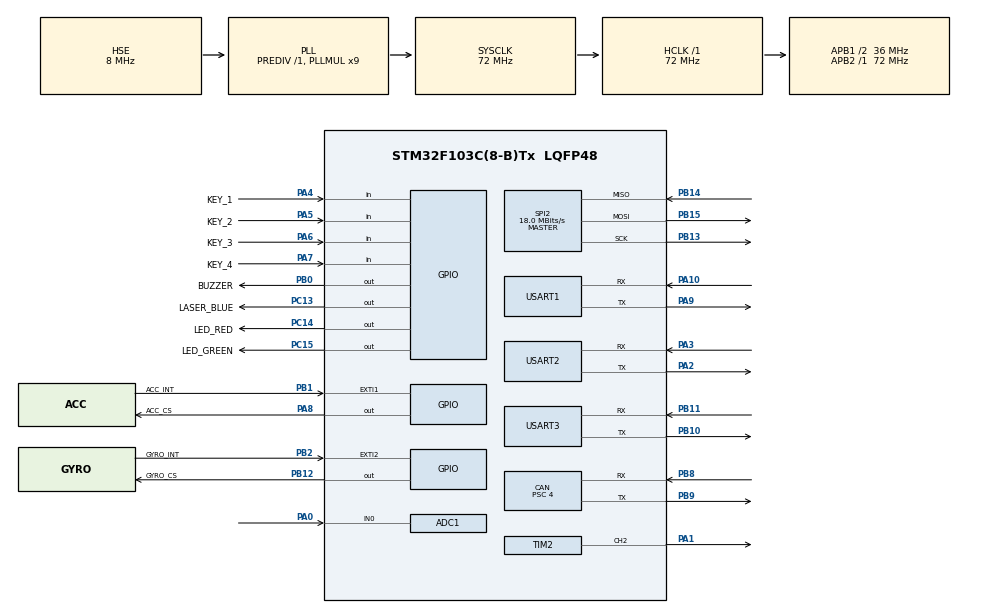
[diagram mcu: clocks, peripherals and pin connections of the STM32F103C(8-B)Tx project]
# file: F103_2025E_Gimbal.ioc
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ADC1.Channel-0\#ChannelRegularConversion=ADC_CHANNEL_0
ADC1.NbrOfConversionFlag=1
ADC1.Rank-0\#ChannelRegularConversion=1
ADC1.SamplingTime-0\#ChannelRegularConversion=ADC_SAMPLETIME_1CYCLE_5
ADC1.master=1
CAN.BS1=CAN_BS1_6TQ
CAN.BS2=CAN_BS2_2TQ
CAN.CalculateBaudRate=1000000
CAN.CalculateTimeBit=1000
CAN.CalculateTimeQuantum=111.11111111111111
CAN.Prescaler=4
Dma.Request0=USART2_RX
Dma.Request1=USART1_RX
Dma.USART1_RX.1.Direction=DMA_PERIPH_TO_MEMORY
Dma.USART1_RX.1.Instance=DMA1_Channel5
Dma.USART1_RX.1.MemDataAlignment=DMA_MDATAALIGN_BYTE
Dma.USART1_RX.1.MemInc=DMA_MINC_ENABLE
Dma.USART1_RX.1.Mode=DMA_NORMAL
Dma.USART1_RX.1.PeriphDataAlignment=DMA_PDATAALIGN_BYTE
Dma.USART1_RX.1.PeriphInc=DMA_PINC_DISABLE
Dma.USART1_RX.1.Priority=DMA_PRIORITY_LOW
Dma.USART2_RX.0.Direction=DMA_PERIPH_TO_MEMORY
Dma.USART2_RX.0.Instance=DMA1_Channel6
Dma.USART2_RX.0.MemDataAlignment=DMA_MDATAALIGN_BYTE
Dma.USART2_RX.0.MemInc=DMA_MINC_ENABLE
Dma.USART2_RX.0.Mode=DMA_NORMAL
Dma.USART2_RX.0.PeriphDataAlignment=DMA_PDATAALIGN_BYTE
Dma.USART2_RX.0.PeriphInc=DMA_PINC_DISABLE
Dma.USART2_RX.0.Priority=DMA_PRIORITY_LOW
FREERTOS.Tasks01=defaultTask,24,256,StartDefaultTask,Default,NULL,Static,defaultTaskBuffer,defaultTaskControlBlock;INSTask_rtos,48,256,IMU_task,As weak,NULL,Static,INSTask_rtosBuffer,INSTask_rtosControlBlock;GIMBALTask_rtos,24,256,GIMBAL_Task,As weak,NULL,Static,GIMBALTask_rtosBuffer,GIMBALTask_rtosControlBlock
FREERTOS.configENABLE_FPU=1
Mcu.Family=STM32F1
Mcu.Name=STM32F103C(8-B)Tx
Mcu.Package=LQFP48
NVIC.DMA1_Channel5_IRQn=true\:5\:0\:false\:false\:true\:true\:false\:true\:true
NVIC.DMA1_Channel6_IRQn=true\:5\:0\:false\:false\:true\:true\:false\:true\:true
NVIC.PriorityGroup=NVIC_PRIORITYGROUP_4
NVIC.TIM1_UP_IRQn=true\:15\:0\:false\:false\:true\:false\:false\:true\:true
NVIC.TimeBase=TIM1_UP_IRQn
NVIC.TimeBaseIP=TIM1
NVIC.USART1_IRQn=true\:5\:0\:false\:false\:true\:true\:true\:true\:true
NVIC.USART2_IRQn=true\:5\:0\:false\:false\:true\:true\:true\:true\:true
NVIC.USB_LP_CAN1_RX0_IRQn=true\:5\:0\:false\:false\:true\:true\:true\:true\:true
PA0-WKUP.Signal=ADCx_IN0
PA1.Signal=S_TIM2_CH2
PA10.Mode=Asynchronous
PA10.Signal=USART1_RX
PA13.Mode=Serial_Wire
PA13.Signal=SYS_JTMS-SWDIO
PA14.Mode=Serial_Wire
PA14.Signal=SYS_JTCK-SWCLK
PA2.Mode=Asynchronous
PA2.Signal=USART2_TX
PA3.Mode=Asynchronous
PA3.Signal=USART2_RX
PA4.GPIO_Label=KEY_1
PA4.Signal=GPIO_Input
PA5.GPIO_Label=KEY_2
PA5.Signal=GPIO_Input
PA6.GPIO_Label=KEY_3
PA6.Signal=GPIO_Input
PA7.GPIO_Label=KEY_4
PA7.Signal=GPIO_Input
PA8.GPIO_Label=ACC_CS
PA8.Signal=GPIO_Output
PA9.Mode=Asynchronous
PA9.Signal=USART1_TX
PB0.GPIO_Label=BUZZER
PB0.Signal=GPIO_Output
PB1.GPIO_Label=ACC_INT
PB1.Signal=GPXTI1
PB10.Mode=Asynchronous
PB10.Signal=USART3_TX
PB11.Mode=Asynchronous
PB11.Signal=USART3_RX
PB12.GPIO_Label=GYRO_CS
PB12.Signal=GPIO_Output
PB13.Mode=Full_Duplex_Master
PB13.Signal=SPI2_SCK
PB14.Mode=Full_Duplex_Master
PB14.Signal=SPI2_MISO
PB15.Mode=Full_Duplex_Master
PB15.Signal=SPI2_MOSI
PB2.GPIO_Label=GYRO_INT
PB2.Signal=GPXTI2
PB8.Mode=CAN_Activate
PB8.Signal=CAN_RX
PB9.Mode=CAN_Activate
PB9.Signal=CAN_TX
PC13-TAMPER-RTC.GPIO_Label=LASER_BLUE
PC13-TAMPER-RTC.Signal=GPIO_Output
PC14-OSC32_IN.GPIO_Label=LED_RED
PC14-OSC32_IN.Signal=GPIO_Output
PC15-OSC32_OUT.GPIO_Label=LED_GREEN
PC15-OSC32_OUT.Signal=GPIO_Output
PD0-OSC_IN.Mode=HSE-External-Oscillator
PD0-OSC_IN.Signal=RCC_OSC_IN
PD1-OSC_OUT.Mode=HSE-External-Oscillator
PD1-OSC_OUT.Signal=RCC_OSC_OUT
ProjectManager.HeapSize=0x400
ProjectManager.StackSize=0x400
ProjectManager.TargetToolchain=MDK-ARM V5.32
RCC.ADCPresc=RCC_ADCPCLK2_DIV6
RCC.AHBFreq_Value=72000000
RCC.APB1CLKDivider=RCC_HCLK_DIV2
RCC.APB1Freq_Value=36000000
RCC.APB1TimFreq_Value=72000000
RCC.APB2Freq_Value=72000000
RCC.APB2TimFreq_Value=72000000
RCC.HCLKFreq_Value=72000000
RCC.PLLMUL=RCC_PLL_MUL9
RCC.PLLSourceVirtual=RCC_PLLSOURCE_HSE
RCC.SYSCLKFreq_VALUE=72000000
RCC.SYSCLKSource=RCC_SYSCLKSOURCE_PLLCLK
RCC.USBFreq_Value=72000000
SH.ADCx_IN0.0=ADC1_IN0,IN0
SH.ADCx_IN0.1=ADC2_IN0
SH.S_TIM2_CH2.0=TIM2_CH2,PWM Generation2 CH2
SPI2.BaudRatePrescaler=SPI_BAUDRATEPRESCALER_2
SPI2.CalculateBaudRate=18.0 MBits/s
SPI2.Direction=SPI_DIRECTION_2LINES
SPI2.Mode=SPI_MODE_MASTER
SPI2.VirtualType=VM_MASTER
TIM2.Channel-PWM\ Generation2\ CH2=TIM_CHANNEL_2
USART1.VirtualMode=VM_ASYNC
USART2.VirtualMode=VM_ASYNC
USART3.VirtualMode=VM_ASYNC
VP_FREERTOS_VS_CMSIS_V2.Mode=CMSIS_V2
VP_SYS_VS_tim1.Mode=TIM1
VP_TIM2_VS_ClockSourceINT.Mode=Internal
board=custom

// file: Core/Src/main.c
/* USER CODE BEGIN Header */
/**
  ******************************************************************************
  * @file           : main.c
  * @brief          : Main program body
  ******************************************************************************
  * @attention
  *
  * Copyright (c) 2026 STMicroelectronics.
  * All rights reserved.
  *
  * This software is licensed under terms that can be found in the LICENSE file
  * in the root directory of this software component.
  * If no LICENSE file comes with this software, it is provided AS-IS.
  *
  ******************************************************************************
  */
/* USER CODE END Header */
#include "main.h"
#include "cmsis_os.h"
#include "adc.h"
#include "can.h"
#include "dma.h"
#include "spi.h"
#include "tim.h"
#include "usart.h"
#include "gpio.h"

/* USER CODE BEGIN Includes */
#include "gimbal.h"
/* USER CODE END Includes */

void SystemClock_Config(void);
void MX_FREERTOS_Init(void);

int main(void)
{

  /* MCU Configuration--------------------------------------------------------*/

  /* Reset of all peripherals, Initializes the Flash interface and the Systick. */
  HAL_Init();

  /* Configure the system clock */
  SystemClock_Config();

  /* Initialize all configured peripherals */
  MX_GPIO_Init();
  MX_DMA_Init();
  MX_ADC1_Init();
  MX_CAN_Init();
  MX_SPI2_Init();
  MX_TIM2_Init();
  MX_USART1_UART_Init();
  MX_USART2_UART_Init();
  MX_USART3_UART_Init();
  /* USER CODE BEGIN 2 */
  My_Main_Init();
  /* USER CODE END 2 */

  /* Init scheduler */
  osKernelInitialize();  /* Call init function for freertos objects (in cmsis_os2.c) */
  MX_FREERTOS_Init();

  /* Start scheduler */
  osKernelStart();

  /* We should never get here as control is now taken by the scheduler */

  /* Infinite loop */
  /* USER CODE BEGIN WHILE */
  while (1)
  {
    My_Main_Task();
    /* USER CODE END WHILE */

  }
}

void SystemClock_Config(void)
{
  RCC_OscInitTypeDef RCC_OscInitStruct = {0};
  RCC_ClkInitTypeDef RCC_ClkInitStruct = {0};
  RCC_PeriphCLKInitTypeDef PeriphClkInit = {0};

  /** Initializes the RCC Oscillators according to the specified parameters
  * in the RCC_OscInitTypeDef structure.
  */
  RCC_OscInitStruct.OscillatorType = RCC_OSCILLATORTYPE_HSE;
  RCC_OscInitStruct.HSEState = RCC_HSE_ON;
  RCC_OscInitStruct.HSEPredivValue = RCC_HSE_PREDIV_DIV1;
  RCC_OscInitStruct.HSIState = RCC_HSI_ON;
  RCC_OscInitStruct.PLL.PLLState = RCC_PLL_ON;
  RCC_OscInitStruct.PLL.PLLSource = RCC_PLLSOURCE_HSE;
  RCC_OscInitStruct.PLL.PLLMUL = RCC_PLL_MUL9;
  if (HAL_RCC_OscConfig(&RCC_OscInitStruct) != HAL_OK)
  {
    Error_Handler();
  }

  /** Initializes the CPU, AHB and APB buses clocks
  */
  RCC_ClkInitStruct.ClockType = RCC_CLOCKTYPE_HCLK|RCC_CLOCKTYPE_SYSCLK
                              |RCC_CLOCKTYPE_PCLK1|RCC_CLOCKTYPE_PCLK2;
  RCC_ClkInitStruct.SYSCLKSource = RCC_SYSCLKSOURCE_PLLCLK;
  RCC_ClkInitStruct.AHBCLKDivider = RCC_SYSCLK_DIV1;
  RCC_ClkInitStruct.APB1CLKDivider = RCC_HCLK_DIV2;
  RCC_ClkInitStruct.APB2CLKDivider = RCC_HCLK_DIV1;

  if (HAL_RCC_ClockConfig(&RCC_ClkInitStruct, FLASH_LATENCY_2) != HAL_OK)
  {
    Error_Handler();
  }
  PeriphClkInit.PeriphClockSelection = RCC_PERIPHCLK_ADC;
  PeriphClkInit.AdcClockSelection = RCC_ADCPCLK2_DIV6;
  if (HAL_RCCEx_PeriphCLKConfig(&PeriphClkInit) != HAL_OK)
  {
    Error_Handler();
  }
}

void HAL_TIM_PeriodElapsedCallback(TIM_HandleTypeDef *htim)
{
  if (htim->Instance == TIM1)
  {
    HAL_IncTick();
  }
}

void Error_Handler(void)
{
  __disable_irq();
  while (1)
  {
  }
}

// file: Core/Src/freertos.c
/* USER CODE BEGIN Header */
/**
 ******************************************************************************
 * File Name          : freertos.c
 * Description        : Code for freertos applications
 ******************************************************************************
 * @attention
 *
 * Copyright (c) 2026 STMicroelectronics.
 * All rights reserved.
 *
 * This software is licensed under terms that can be found in the LICENSE file
 * in the root directory of this software component.
 * If no LICENSE file comes with this software, it is provided AS-IS.
 *
 ******************************************************************************
 */
/* USER CODE END Header */

#include "FreeRTOS.h"
#include "task.h"
#include "main.h"
#include "cmsis_os.h"

/* USER CODE BEGIN Includes */
#include "algorithm.h"
/* USER CODE END Includes */

typedef StaticTask_t osStaticThreadDef_t;

/* Definitions for defaultTask */
osThreadId_t defaultTaskHandle;
uint32_t defaultTaskBuffer[256];
osStaticThreadDef_t defaultTaskControlBlock;
const osThreadAttr_t defaultTask_attributes = {
        .name = "defaultTask",
        .cb_mem = &defaultTaskControlBlock,
        .cb_size = sizeof(defaultTaskControlBlock),
        .stack_mem = &defaultTaskBuffer[0],
        .stack_size = sizeof(defaultTaskBuffer),
        .priority = (osPriority_t)osPriorityNormal,
};
/* Definitions for INSTask_rtos */
osThreadId_t INSTask_rtosHandle;
uint32_t INSTask_rtosBuffer[256];
osStaticThreadDef_t INSTask_rtosControlBlock;
const osThreadAttr_t INSTask_rtos_attributes = {
        .name = "INSTask_rtos",
        .cb_mem = &INSTask_rtosControlBlock,
        .cb_size = sizeof(INSTask_rtosControlBlock),
        .stack_mem = &INSTask_rtosBuffer[0],
        .stack_size = sizeof(INSTask_rtosBuffer),
        .priority = (osPriority_t)osPriorityRealtime,
};
/* Definitions for GIMBALTask_rtos */
osThreadId_t GIMBALTask_rtosHandle;
uint32_t GIMBALTask_rtosBuffer[256];
osStaticThreadDef_t GIMBALTask_rtosControlBlock;
const osThreadAttr_t GIMBALTask_rtos_attributes = {
        .name = "GIMBALTask_rtos",
        .cb_mem = &GIMBALTask_rtosControlBlock,
        .cb_size = sizeof(GIMBALTask_rtosControlBlock),
        .stack_mem = &GIMBALTask_rtosBuffer[0],
        .stack_size = sizeof(GIMBALTask_rtosBuffer),
        .priority = (osPriority_t)osPriorityNormal,
};

void StartDefaultTask(void *argument);
void IMU_task(void *argument);
void GIMBAL_Task(void *argument);

void MX_FREERTOS_Init(void); /* (MISRA C 2004 rule 8.1) */

void MX_FREERTOS_Init(void)
{

    /* Create the thread(s) */
    /* creation of defaultTask */
    defaultTaskHandle = osThreadNew(StartDefaultTask, NULL, &defaultTask_attributes);

    /* creation of INSTask_rtos */
    INSTask_rtosHandle = osThreadNew(IMU_task, NULL, &INSTask_rtos_attributes);

    /* creation of GIMBALTask_rtos */
    GIMBALTask_rtosHandle = osThreadNew(GIMBAL_Task, NULL, &GIMBALTask_rtos_attributes);

}

void StartDefaultTask(void *argument)
{
    /* USER CODE BEGIN StartDefaultTask */
    /* Infinite loop */
    for (;;)
    {
        vofa_start();
        osDelay(1);
    }
    /* USER CODE END StartDefaultTask */
}

__weak void IMU_task(void *argument)
{
    for (;;)
    {
        osDelay(1);
    }
}

__weak void GIMBAL_Task(void *argument)
{
    for (;;)
    {
        osDelay(1);
    }
}
